VERSION ""

NS_ :

BS_:

BU_: VCU BMS

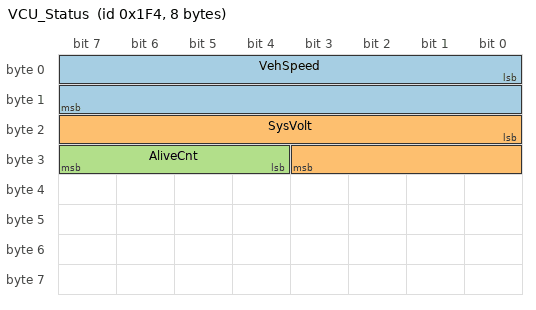
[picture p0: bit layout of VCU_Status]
BO_ 500 VCU_Status: 8 VCU
 SG_ VehSpeed : 0|16@1+ (0.01,0) [0|655.35] "km/h" BMS
 SG_ SysVolt : 16|12@1+ (0.1,0) [0|409.5] "V" BMS
 SG_ AliveCnt : 28|4@1+ (1,0) [0|15] "" BMS

CM_ BO_ 500 "VCU status frame";
CM_ SG_ 500 VehSpeed "Vehicle speed";
BA_DEF_ BO_ "GenMsgCycleTime" INT 0 65535;
BA_DEF_DEF_ "GenMsgCycleTime" 100;
